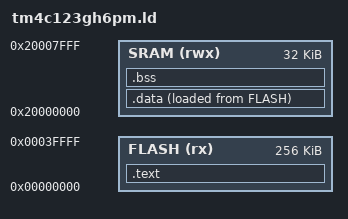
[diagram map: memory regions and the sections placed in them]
ENTRY(Reset_Handler)

MEMORY
{
    FLASH (rx)  : ORIGIN = 0x00000000, LENGTH = 256K
    SRAM  (rwx) : ORIGIN = 0x20000000, LENGTH = 32K
}

_estack = ORIGIN(SRAM) + LENGTH(SRAM);

SECTIONS
{
    .text :
    {
        KEEP(*(.isr_vector))
        *(.text*)
        *(.rodata*)
    } > FLASH

    .data :
    {
        *(.data*)
    } > SRAM AT > FLASH

    .bss :
    {
        *(.bss*)
        *(COMMON)
    } > SRAM
}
